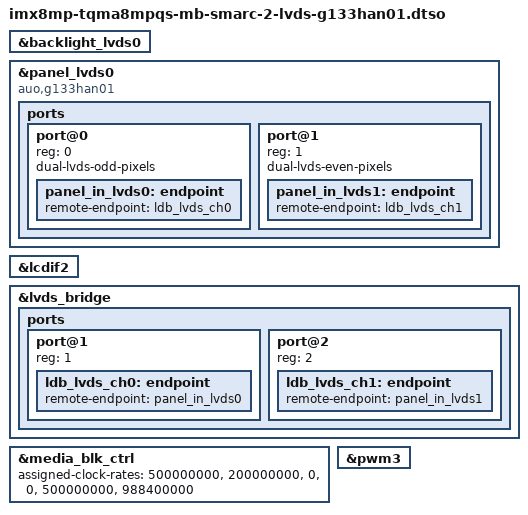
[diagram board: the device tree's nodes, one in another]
// SPDX-License-Identifier: (GPL-2.0-or-later OR MIT)
/*
 * Copyright (c) 2025-2026 TQ-Systems GmbH <linux@ew.tq-group.com>,
 * D-82229 Seefeld, Germany.
 * Author: Martin Schmiedel
 */

/dts-v1/;
/plugin/;

&backlight_lvds0 {
	status = "okay";
};

&panel_lvds0 {
	compatible = "auo,g133han01";
	status = "okay";

	ports {
		#address-cells = <1>;
		#size-cells = <0>;

		port@0 {
			reg = <0>;
			dual-lvds-odd-pixels;

			panel_in_lvds0: endpoint {
				remote-endpoint = <&ldb_lvds_ch0>;
			};
		};

		port@1 {
			reg = <1>;
			dual-lvds-even-pixels;

			panel_in_lvds1: endpoint {
				remote-endpoint = <&ldb_lvds_ch1>;
			};
		};
	};
};

&lcdif2 {
	status = "okay";
};

&lvds_bridge {
	status = "okay";

	ports {
		#address-cells = <1>;
		#size-cells = <0>;

		port@1 {
			reg = <1>;

			ldb_lvds_ch0: endpoint {
				remote-endpoint = <&panel_in_lvds0>;
			};
		};

		port@2 {
			reg = <2>;

			ldb_lvds_ch1: endpoint {
				remote-endpoint = <&panel_in_lvds1>;
			};
		};
	};
};

// Update VIDEO_PLL1 frequency
&media_blk_ctrl {
	assigned-clock-rates = <500000000>, <200000000>,
			       <0>, <0>, <500000000>,
			       <988400000>;
};

&pwm3 {
	status = "okay";
};
